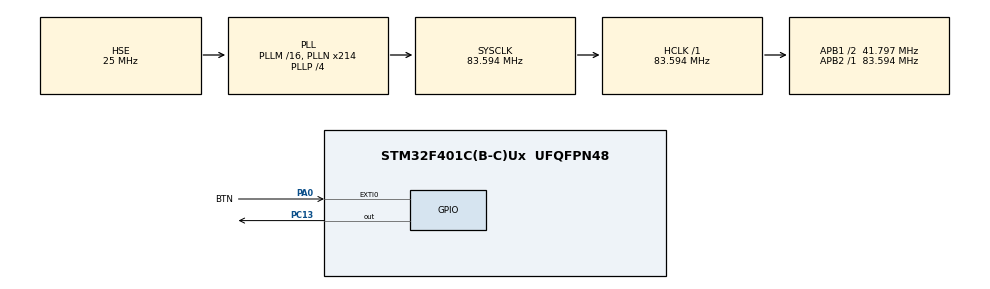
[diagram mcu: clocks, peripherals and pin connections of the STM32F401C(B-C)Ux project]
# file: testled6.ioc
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Mcu.Family=STM32F4
Mcu.Name=STM32F401C(B-C)Ux
Mcu.Package=UFQFPN48
NVIC.EXTI0_IRQn=true\:0\:0\:false\:false\:true\:true\:true\:true
NVIC.PriorityGroup=NVIC_PRIORITYGROUP_4
PA0-WKUP.GPIO_Label=BTN
PA0-WKUP.GPIO_PuPd=GPIO_PULLUP
PA0-WKUP.Signal=GPXTI0
PA13.Mode=Trace_Asynchronous_SW
PA13.Signal=SYS_JTMS-SWDIO
PA14.Mode=Trace_Asynchronous_SW
PA14.Signal=SYS_JTCK-SWCLK
PB3.Mode=Trace_Asynchronous_SW
PB3.Signal=SYS_JTDO-SWO
PC13-ANTI_TAMP.Signal=GPIO_Output
PC14-OSC32_IN.Mode=LSE-External-Oscillator
PC14-OSC32_IN.Signal=RCC_OSC32_IN
PC15-OSC32_OUT.Mode=LSE-External-Oscillator
PC15-OSC32_OUT.Signal=RCC_OSC32_OUT
PH0\ -\ OSC_IN.Mode=HSE-External-Oscillator
PH0\ -\ OSC_IN.Signal=RCC_OSC_IN
PH1\ -\ OSC_OUT.Mode=HSE-External-Oscillator
PH1\ -\ OSC_OUT.Signal=RCC_OSC_OUT
ProjectManager.HeapSize=0x200
ProjectManager.StackSize=0x400
ProjectManager.TargetToolchain=STM32CubeIDE
RCC.48MHZClocksFreq_Value=83593750
RCC.AHBFreq_Value=83593750
RCC.APB1CLKDivider=RCC_HCLK_DIV2
RCC.APB1Freq_Value=41796875
RCC.APB1TimFreq_Value=83593750
RCC.APB2Freq_Value=83593750
RCC.APB2TimFreq_Value=83593750
RCC.CortexFreq_Value=83593750
RCC.EnbaleCSS=true
RCC.HCLKFreq_Value=83593750
RCC.HSE_VALUE=25000000
RCC.HSI_VALUE=16000000
RCC.PLLN=214
RCC.PLLP=RCC_PLLP_DIV4
RCC.PLLSourceVirtual=RCC_PLLSOURCE_HSE
RCC.SYSCLKFreq_VALUE=83593750
RCC.SYSCLKSource=RCC_SYSCLKSOURCE_PLLCLK
RCC.VCOOutputFreq_Value=334375000
board=custom

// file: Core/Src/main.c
/* USER CODE BEGIN Header */
/**
  ******************************************************************************
  * @file           : main.c
  * @brief          : Main program body
  ******************************************************************************
  * @attention
  *
  * Copyright (c) 2026 STMicroelectronics.
  * All rights reserved.
  *
  * This software is licensed under terms that can be found in the LICENSE file
  * in the root directory of this software component.
  * If no LICENSE file comes with this software, it is provided AS-IS.
  *
  ******************************************************************************
  */
/* USER CODE END Header */
#include "main.h"

/* USER CODE BEGIN Includes */
#include "core_cm4.h"
/* USER CODE END Includes */

/* USER CODE BEGIN PV */
/* Переменные для обработки кнопки и PWM */
volatile uint8_t pwm_rabotaet = 0;      /* Флаг активного PWM режима: 0 - выкл, 1 - вкл */
uint8_t tsikl_raboty_pwm = 0;           /* Текущий duty cycle PWM (0-100) */
uint8_t napravlenie_izmeneniya = 0;     /* Направление изменения PWM: 0 - рост, 1 - спад */
/* USER CODE END PV */

void SystemClock_Config(void);
static void MX_GPIO_Init(void);

/* USER CODE BEGIN 0 */

/* Задержка в микросекундах для PWM */
static void MicrosecondDelay(uint32_t us)
{
  uint32_t start = DWT->CYCCNT;
  uint32_t freq = HAL_RCC_GetHCLKFreq() / 100000;  /* Частота в МГц */
  while ((DWT->CYCCNT - start) < (us * freq));
}

/* Функция программного PWM для светодиода
 * Светодиод на PC13 активный низкий (0 = горит, 1 = выкл)
 */
static void SoftwarePWM(uint8_t duty)
{
  /* Светодиод ГОРИТ на duty% периода (низкий уровень) */
  HAL_GPIO_WritePin(GPIOC, GPIO_PIN_13, GPIO_PIN_RESET);
  MicrosecondDelay(duty * 10);  /* 10 мкс на 1% duty cycle */

  /* Светодиод ВЫКЛЮЧЕН на (100-duty)% периода (высокий уровень) */
  HAL_GPIO_WritePin(GPIOC, GPIO_PIN_13, GPIO_PIN_SET);
  MicrosecondDelay((100 - duty) * 10);
}

/* Функция плавного изменения яркости */
static void BrightnessControl(void)
{
  if (napravlenie_izmeneniya == 0)
  {
    tsikl_raboty_pwm++;
    if (tsikl_raboty_pwm >= 100)
    {
      tsikl_raboty_pwm = 100;
      napravlenie_izmeneniya = 1;  /* Меняем направление на спад */
    }
  }
  else
  {
    tsikl_raboty_pwm--;
    if (tsikl_raboty_pwm == 0)
    {
      tsikl_raboty_pwm = 0;
      napravlenie_izmeneniya = 0;  /* Меняем направление на рост */
    }
  }
}

/* USER CODE END 0 */

int main(void)
{

  /* MCU Configuration--------------------------------------------------------*/

  /* Сброс всех периферийных устройств, инициализация Flash интерфейса и Systick */
  HAL_Init();

  /* Configure the system clock */
  SystemClock_Config();

  /* Initialize all configured peripherals */
  MX_GPIO_Init();
  /* USER CODE BEGIN 2 */
  /* Инициализация DWT для задержек в микросекундах */
  CoreDebug->DEMCR |= CoreDebug_DEMCR_TRCENA_Msk;
  DWT->CYCCNT = 0;
  DWT->CTRL |= DWT_CTRL_CYCCNTENA_Msk;

  /* Инициализация переменных PWM - по умолчанию светодиод выключен */
  pwm_rabotaet = 0;
  tsikl_raboty_pwm = 0;
  napravlenie_izmeneniya = 0;

  /* Выключаем светодиод (инверсный выход: SET = 1 = не горит) */
  HAL_GPIO_WritePin(GPIOC, GPIO_PIN_13, GPIO_PIN_SET);
  /* USER CODE END 2 */

  /* Infinite loop */
  while (1)
  {

    /* USER CODE BEGIN 3 */
    if (pwm_rabotaet)
    {
      /* PWM режим: светодиод мигает с изменяемой яркостью */
      SoftwarePWM(tsikl_raboty_pwm);
      BrightnessControl();
    }
    else
    {
      /* LED выключен (инверсный выход: SET = 1 = не горит) */
      HAL_GPIO_WritePin(GPIOC, GPIO_PIN_13, GPIO_PIN_SET);
    }
  }
  /* USER CODE END 3 */
}

void SystemClock_Config(void)
{
  RCC_OscInitTypeDef RCC_OscInitStruct = {0};
  RCC_ClkInitTypeDef RCC_ClkInitStruct = {0};

  /** Configure the main internal regulator output voltage
  */
  __HAL_RCC_PWR_CLK_ENABLE();
  __HAL_PWR_VOLTAGESCALING_CONFIG(PWR_REGULATOR_VOLTAGE_SCALE2);

  /** Initializes the RCC Oscillators according to the specified parameters
  * in the RCC_OscInitTypeDef structure.
  */
  RCC_OscInitStruct.OscillatorType = RCC_OSCILLATORTYPE_HSE;
  RCC_OscInitStruct.HSEState = RCC_HSE_ON;
  RCC_OscInitStruct.PLL.PLLState = RCC_PLL_ON;
  RCC_OscInitStruct.PLL.PLLSource = RCC_PLLSOURCE_HSE;
  RCC_OscInitStruct.PLL.PLLM = 16;
  RCC_OscInitStruct.PLL.PLLN = 214;
  RCC_OscInitStruct.PLL.PLLP = RCC_PLLP_DIV4;
  RCC_OscInitStruct.PLL.PLLQ = 4;
  if (HAL_RCC_OscConfig(&RCC_OscInitStruct) != HAL_OK)
  {
    Error_Handler();
  }

  /** Initializes the CPU, AHB and APB buses clocks
  */
  RCC_ClkInitStruct.ClockType = RCC_CLOCKTYPE_HCLK|RCC_CLOCKTYPE_SYSCLK
                              |RCC_CLOCKTYPE_PCLK1|RCC_CLOCKTYPE_PCLK2;
  RCC_ClkInitStruct.SYSCLKSource = RCC_SYSCLKSOURCE_PLLCLK;
  RCC_ClkInitStruct.AHBCLKDivider = RCC_SYSCLK_DIV1;
  RCC_ClkInitStruct.APB1CLKDivider = RCC_HCLK_DIV2;
  RCC_ClkInitStruct.APB2CLKDivider = RCC_HCLK_DIV1;

  if (HAL_RCC_ClockConfig(&RCC_ClkInitStruct, FLASH_LATENCY_2) != HAL_OK)
  {
    Error_Handler();
  }

  /** Enables the Clock Security System
  */
  HAL_RCC_EnableCSS();
}

static void MX_GPIO_Init(void)
{
  GPIO_InitTypeDef GPIO_InitStruct = {0};

  /* GPIO Ports Clock Enable */
  __HAL_RCC_GPIOC_CLK_ENABLE();
  __HAL_RCC_GPIOH_CLK_ENABLE();
  __HAL_RCC_GPIOA_CLK_ENABLE();
  __HAL_RCC_GPIOB_CLK_ENABLE();

  /*Configure GPIO pin Output Level */
  HAL_GPIO_WritePin(GPIOC, GPIO_PIN_13, GPIO_PIN_RESET);

  /*Configure GPIO pin : PC13 */
  GPIO_InitStruct.Pin = GPIO_PIN_13;
  GPIO_InitStruct.Mode = GPIO_MODE_OUTPUT_PP;
  GPIO_InitStruct.Pull = GPIO_NOPULL;
  GPIO_InitStruct.Speed = GPIO_SPEED_FREQ_LOW;
  HAL_GPIO_Init(GPIOC, &GPIO_InitStruct);

  /*Configure GPIO pin : BTN_Pin */
  GPIO_InitStruct.Pin = BTN_Pin;
  GPIO_InitStruct.Mode = GPIO_MODE_IT_FALLING;
  GPIO_InitStruct.Pull = GPIO_PULLUP;
  HAL_GPIO_Init(BTN_GPIO_Port, &GPIO_InitStruct);

  /* EXTI interrupt init*/
  HAL_NVIC_SetPriority(EXTI0_IRQn, 0, 0);
  HAL_NVIC_EnableIRQ(EXTI0_IRQn);

}

/* USER CODE BEGIN 4 */

/* Простая задержка для антидребезга без HAL_Delay */
static void SimpleDelay(uint32_t ms)
{
  for (uint32_t i = 0; i < ms * 8000; i++)  /* Примерно 1 мс при 8 MHz */
  {
    __NOP();
  }
}

/* Обработчик прерывания от кнопки (вызывается из stm32f4xx_it.c) */
void HAL_GPIO_EXTI_Callback(uint16_t GPIO_Pin)
{
  if (GPIO_Pin == BTN_Pin)  /* Кнопка на PA0 */
  {
    /* Антидребезг */
    SimpleDelay(20);

    /* Проверяем, что кнопка всё ещё нажата (активный низкий уровень) */
    if (HAL_GPIO_ReadPin(BTN_GPIO_Port, BTN_Pin) == GPIO_PIN_RESET)
    {
      /* Переключаем режим PWM */
      pwm_rabotaet = !pwm_rabotaet;
    }
  }
}

/* USER CODE END 4 */

void Error_Handler(void)
{
  /* USER CODE BEGIN Error_Handler_Debug */
  /* Пользователь может добавить свою реализацию для отчета о состоянии ошибки HAL */
  __disable_irq();
  while (1)
  {
  }
  /* USER CODE END Error_Handler_Debug */
}
#ifdef USE_FULL_ASSERT
/**
  * @brief  Сообщает имя исходного файла и номер строки,
  *         где произошла ошибка assert_param.
  * @param  file: указатель на имя исходного файла
  * @param  line: номер строки исходного файла с ошибкой assert_param
  * @retval None
  */
void assert_failed(uint8_t *file, uint32_t line)
{
  /* USER CODE BEGIN 6 */
  /* Пользователь может добавить свою реализацию для отчета имени файла и номера строки,
     например: printf("Неверные параметры значения: файл %s на строке %d\r\n", file, line) */
  /* USER CODE END 6 */
}
#endif /* USE_FULL_ASSERT */
